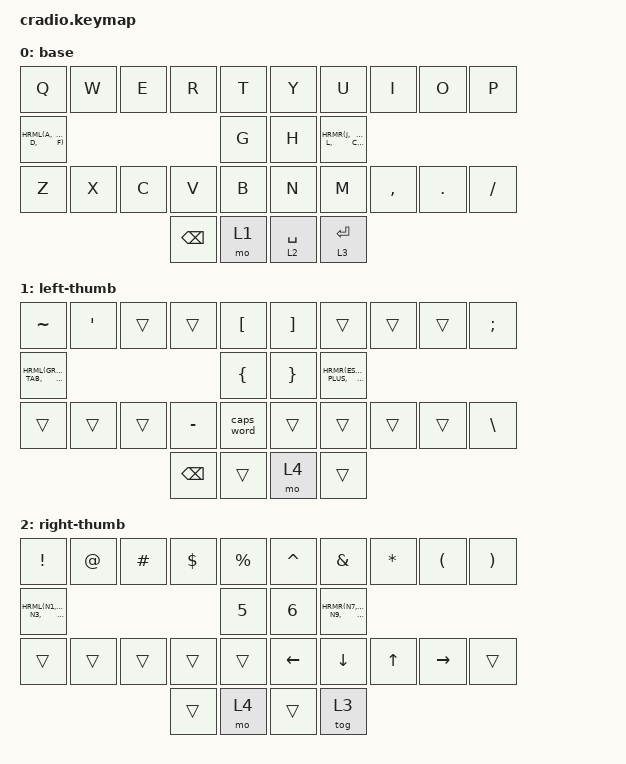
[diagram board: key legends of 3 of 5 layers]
// Copyright (c) 2022 The ZMK Contributors
// SPDX-License-Identifier: MIT

#define ZMK_POINTING_DEFAULT_MOVE_VAL 1500 // default 600

#include <behaviors.dtsi>
#include <dt-bindings/zmk/bt.h>
#include <dt-bindings/zmk/keys.h>
#include <dt-bindings/zmk/pointing.h>

// Home row mods macro
#define HRML(k1,k2,k3,k4) &bhm LSHFT k1  &bhm LCTRL k2  &bhm LALT k3  &bhm LGUI k4
#define HRMR(k1,k2,k3,k4) &bhm RGUI k1  &bhm RALT k2  &bhm RCTRL k3  &bhm RSHFT k4

#define BT_M_SEL(k1, k2, k3, k4, k5) &bt BT_SEL k1 &bt BT_SEL k2 &bt BT_SEL k3 &bt BT_SEL k4 &bt BT_SEL k5

&caps_word {
    continue-list = <UNDERSCORE>;
};

/ {
    behaviors {
        bhm: balanced_homerow_mods {
            compatible = "zmk,behavior-hold-tap";
            #binding-cells = <2>;
            tapping-term-ms = <200>;
            quick-tap-ms = <0>;
            flavor = "balanced";
            bindings = <&kp>, <&kp>;
        };
    };
};

/ {
    keymap {
        compatible = "zmk,keymap";

        // layer 0
        base {
            bindings = <
// ╭───────────┬───────────┬───────────┬───────────┬───────────╮ ╭───────────┬───────────┬───────────┬───────────┬───────────╮
        &kp Q       &kp W       &kp E       &kp R       &kp T       &kp Y       &kp U       &kp I       &kp O       &kp P
// ├───────────┼───────────┼───────────┼───────────┼───────────┤ ├───────────┼───────────┼───────────┼───────────┼───────────┤
        HRML(A,     S,          D,          F)          &kp G       &kp H       HRMR(J,     K,          L,          COLON)
// ├───────────┼───────────┼───────────┼───────────┼───────────┤ ├───────────┼───────────┼───────────┼───────────┼───────────┤
        &kp Z       &kp X       &kp C       &kp V       &kp B       &kp N       &kp M       &kp COMMA   &kp DOT     &kp FSLH
// ╰───────────┴───────────┴───────────┼───────────┼───────────┤ ├───────────┼───────────┼───────────┴───────────┴───────────╯
                                            &kp BSPC    &mo 1       &lt 2 SPACE &lt 3 RET
//                                     ╰───────────┴───────────╯ ╰───────────┴───────────╯
            >;
        };

        // layer 1
        left-thumb {
            bindings = <
// ╭───────────┬───────────┬───────────┬───────────┬───────────╮ ╭───────────┬───────────┬───────────┬───────────┬───────────╮
        &kp TILDE   &kp SQT     &trans      &trans      &kp LBKT     &kp RBKT   &trans      &trans      &trans      &kp SEMI
// ├───────────┼───────────┼───────────┼───────────┼───────────┤ ├───────────┼───────────┼───────────┼───────────┼───────────┤
        HRML(GRAVE, DQT,        TAB,        UNDER)      &kp LBRC     &kp RBRC   HRMR(ESC,   EQUAL,      PLUS,       PIPE)
// ├───────────┼───────────┼───────────┼───────────┼───────────┤ ├───────────┼───────────┼───────────┼───────────┼───────────┤
        &trans      &trans      &trans      &kp MINUS   &caps_word   &trans     &trans      &trans      &trans      &kp BSLH
// ╰───────────┴───────────┴───────────┼───────────┼───────────┤ ├───────────┼───────────┼───────────┴───────────┴───────────╯
                                            &kp BSPC    &trans       &mo 4      &trans
//                                     ╰───────────┴───────────╯ ╰───────────┴───────────╯
            >;
        };

        // layer 2
        right-thumb {
            bindings = <
// ╭───────────┬───────────┬───────────┬───────────┬───────────╮ ╭───────────┬───────────┬───────────┬───────────┬───────────╮
        &kp EXCL    &kp AT      &kp HASH    &kp DLLR    &kp PRCNT   &kp CARET   &kp AMPS    &kp STAR    &kp LPAR    &kp RPAR
// ├───────────┼───────────┼───────────┼───────────┼───────────┤ ├───────────┼───────────┼───────────┼───────────┼───────────┤
        HRML(N1,    N2,         N3,         N4)         &kp N5      &kp N6      HRMR(N7,    N8,         N9,         N0)
// ├───────────┼───────────┼───────────┼───────────┼───────────┤ ├───────────┼───────────┼───────────┼───────────┼───────────┤
        &trans      &trans      &trans      &trans      &trans      &kp LEFT    &kp DOWN    &kp UP      &kp RIGHT   &trans
// ╰───────────┴───────────┴───────────┼───────────┼───────────┤ ├───────────┼───────────┼───────────┴───────────┴───────────╯
                                            &trans      &mo 4       &trans      &tog 3
//                                     ╰───────────┴───────────╯ ╰───────────┴───────────╯
            >;
        };

        // layer 3
        mouse-and-bluetooth {
            bindings = <
// ╭───────────┬───────────┬───────────┬───────────┬───────────╮ ╭───────────┬───────────┬───────────┬───────────┬───────────╮
    &bt BT_CLR_ALL &bt BT_CLR &trans &trans &trans          &kp C_VOL_UP     &mkp LCLK       &mmv MOVE_UP    &mkp RCLK       &kp C_BRI_UP
// ├───────────┼───────────┼───────────┼───────────┼───────────┤ ├───────────┼───────────┼───────────┼───────────┼───────────┤
    &trans &trans &trans &trans &trans                      &kp C_VOL_DN     &mmv MOVE_LEFT  &mmv MOVE_DOWN  &mmv MOVE_RIGHT &kp C_BRI_DN
// ├───────────┼───────────┼───────────┼───────────┼───────────┤ ├───────────┼───────────┼───────────┼───────────┼───────────┤
    BT_M_SEL(0, 1, 2, 3, 4)                                         &kp LEFT    &kp DOWN    &kp UP      &kp RIGHT   &trans
// ╰───────────┴───────────┴───────────┼───────────┼───────────┤ ├───────────┼───────────┼───────────┴───────────┴───────────╯
                                            &trans      &trans      &trans      &tog 3
//                                     ╰───────────┴───────────╯ ╰───────────┴───────────╯

            >;
        };

        // layer 4
        meta {
            bindings = <
// ╭───────────┬───────────┬───────────┬───────────┬───────────╮ ╭───────────┬───────────┬───────────┬───────────┬───────────╮
     &kp F1        &kp F2      &kp F3     &kp F4      &kp F5        &kp F6      &kp F7      &kp F8      &kp F9      &kp F10
// ├───────────┼───────────┼───────────┼───────────┼───────────┤ ├───────────┼───────────┼───────────┼───────────┼───────────┤
     &kp LSHIFT    &kp LCTRL   &kp LEFT_ALT  &kp LGUI     &trans    &trans      &trans      &trans      &trans      &trans
// ├───────────┼───────────┼───────────┼───────────┼───────────┤ ├───────────┼───────────┼───────────┼───────────┼───────────┤
     &trans        &trans     &trans      &trans      &trans        &kp F11     &kp F12     &trans    &sys_reset  &bootloader
// ╰───────────┴───────────┴───────────┼───────────┼───────────┤ ├───────────┼───────────┼───────────┴───────────┴───────────╯
                                          &trans      &trans        &trans      &trans
//                                     ╰───────────┴───────────╯ ╰───────────┴───────────╯
            >;
        };
    };
};
